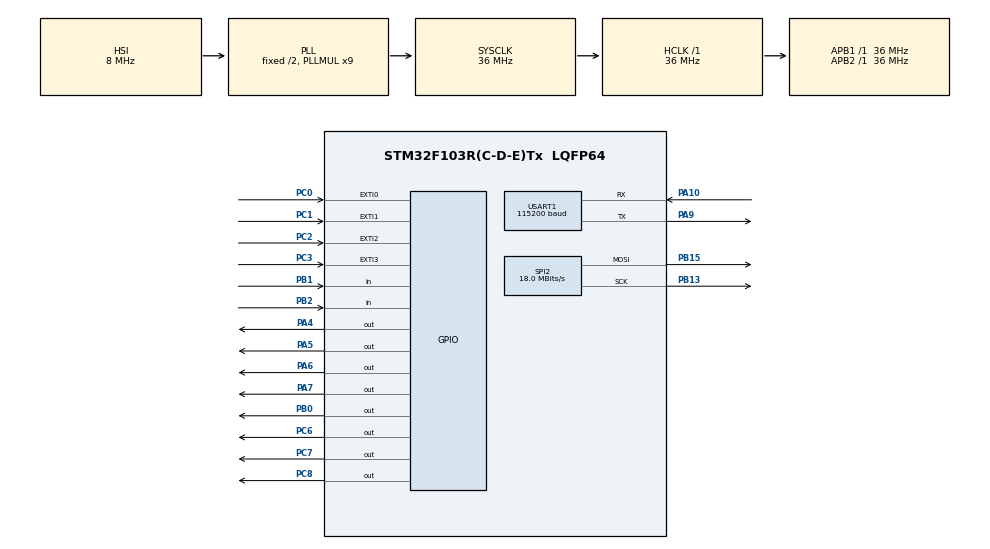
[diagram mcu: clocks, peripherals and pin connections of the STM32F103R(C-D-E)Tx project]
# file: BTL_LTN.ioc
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Mcu.Family=STM32F1
Mcu.Name=STM32F103R(C-D-E)Tx
Mcu.Package=LQFP64
NVIC.EXTI0_IRQn=true\:7\:0\:true\:false\:true\:true\:true\:true
NVIC.EXTI1_IRQn=true\:7\:0\:true\:false\:true\:true\:true\:true
NVIC.EXTI2_IRQn=true\:7\:0\:true\:false\:true\:true\:true\:true
NVIC.EXTI3_IRQn=true\:7\:0\:true\:false\:true\:true\:true\:true
NVIC.PriorityGroup=NVIC_PRIORITYGROUP_4
NVIC.SPI2_IRQn=true\:1\:0\:true\:false\:true\:true\:true\:true
NVIC.TIM1_UP_IRQn=true\:7\:0\:true\:false\:true\:true\:true\:true
NVIC.TIM4_IRQn=true\:15\:0\:false\:false\:true\:false\:true\:true
NVIC.TimeBase=TIM4_IRQn
NVIC.TimeBaseIP=TIM4
NVIC.USART1_IRQn=true\:6\:0\:true\:false\:true\:true\:true\:true
PA10.Mode=Asynchronous
PA10.Signal=USART1_RX
PA13.Mode=Serial_Wire
PA13.Signal=SYS_JTMS-SWDIO
PA14.Mode=Serial_Wire
PA14.Signal=SYS_JTCK-SWCLK
PA4.GPIO_ModeDefaultOutputPP=GPIO_MODE_OUTPUT_PP
PA4.GPIO_PuPd=GPIO_PULLUP
PA4.PinState=GPIO_PIN_SET
PA4.Signal=GPIO_Output
PA5.GPIO_PuPd=GPIO_PULLUP
PA5.PinState=GPIO_PIN_SET
PA5.Signal=GPIO_Output
PA6.GPIO_PuPd=GPIO_PULLUP
PA6.PinState=GPIO_PIN_SET
PA6.Signal=GPIO_Output
PA7.GPIO_PuPd=GPIO_PULLUP
PA7.PinState=GPIO_PIN_SET
PA7.Signal=GPIO_Output
PA9.Mode=Asynchronous
PA9.Signal=USART1_TX
PB0.GPIO_ModeDefaultOutputPP=GPIO_MODE_OUTPUT_OD
PB0.GPIO_PuPd=GPIO_PULLUP
PB0.PinState=GPIO_PIN_SET
PB0.Signal=GPIO_Output
PB1.GPIO_PuPd=GPIO_PULLUP
PB1.Signal=GPIO_Input
PB13.Mode=TX_Only_Simplex_Unidirect_Master
PB13.Signal=SPI2_SCK
PB15.Mode=TX_Only_Simplex_Unidirect_Master
PB15.Signal=SPI2_MOSI
PB2.GPIO_PuPd=GPIO_PULLUP
PB2.Signal=GPIO_Input
PC0.GPIO_ModeDefaultEXTI=GPIO_MODE_IT_FALLING
PC0.GPIO_PuPd=GPIO_PULLUP
PC0.Signal=GPXTI0
PC1.GPIO_ModeDefaultEXTI=GPIO_MODE_IT_FALLING
PC1.GPIO_PuPd=GPIO_PULLUP
PC1.Signal=GPXTI1
PC2.GPIO_ModeDefaultEXTI=GPIO_MODE_IT_FALLING
PC2.GPIO_PuPd=GPIO_PULLUP
PC2.Signal=GPXTI2
PC3.GPIO_ModeDefaultEXTI=GPIO_MODE_IT_FALLING
PC3.GPIO_PuPd=GPIO_PULLUP
PC3.Signal=GPXTI3
PC6.GPIO_PuPd=GPIO_PULLUP
PC6.Signal=GPIO_Output
PC7.GPIO_PuPd=GPIO_PULLUP
PC7.Signal=GPIO_Output
PC8.GPIO_PuPd=GPIO_PULLUP
PC8.Signal=GPIO_Output
PD0-OSC_IN.Mode=HSE-External-Oscillator
PD0-OSC_IN.Signal=RCC_OSC_IN
PD1-OSC_OUT.Mode=HSE-External-Oscillator
PD1-OSC_OUT.Signal=RCC_OSC_OUT
ProjectManager.HeapSize=0x200
ProjectManager.StackSize=0x400
ProjectManager.TargetToolchain=STM32CubeIDE
RCC.AHBFreq_Value=36000000
RCC.APB1Freq_Value=36000000
RCC.APB1TimFreq_Value=36000000
RCC.APB2Freq_Value=36000000
RCC.APB2TimFreq_Value=36000000
RCC.HCLKFreq_Value=36000000
RCC.PLLMUL=RCC_PLL_MUL9
RCC.SYSCLKFreq_VALUE=36000000
RCC.SYSCLKSource=RCC_SYSCLKSOURCE_PLLCLK
RCC.USBFreq_Value=36000000
SPI2.CalculateBaudRate=18.0 MBits/s
SPI2.Direction=SPI_DIRECTION_2LINES
SPI2.Mode=SPI_MODE_MASTER
SPI2.VirtualType=VM_MASTER
TIM1.AutoReloadPreload=TIM_AUTORELOAD_PRELOAD_ENABLE
TIM1.Period=10000
TIM1.Prescaler=35999
TIM2.Prescaler=35999
TIM3.Prescaler=35
USART1.BaudRate=115200
USART1.Parity=PARITY_NONE
USART1.VirtualMode=VM_ASYNC
VP_SYS_VS_tim4.Mode=TIM4
VP_TIM1_VS_ClockSourceINT.Mode=Internal
VP_TIM2_VS_ClockSourceINT.Mode=Internal
VP_TIM3_VS_ClockSourceINT.Mode=Internal
board=custom

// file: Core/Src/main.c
/* USER CODE BEGIN Header */
/**
  ******************************************************************************
  * @file           : main.c
  * @brief          : Main program body
  ******************************************************************************
  * @attention
  *
  * Copyright (c) 2024 STMicroelectronics.
  * All rights reserved.
  *
  * This software is licensed under terms that can be found in the LICENSE file
  * in the root directory of this software component.
  * If no LICENSE file comes with this software, it is provided AS-IS.
  *
  ******************************************************************************
  */
/* USER CODE END Header */
#include "main.h"

/* USER CODE BEGIN Includes */
#include "app.h"
/* USER CODE END Includes */

SPI_HandleTypeDef hspi2;

TIM_HandleTypeDef htim1;
TIM_HandleTypeDef htim2;
TIM_HandleTypeDef htim3;

UART_HandleTypeDef huart1;

void SystemClock_Config(void);
static void MX_GPIO_Init(void);
static void MX_TIM1_Init(void);
static void MX_TIM2_Init(void);
static void MX_TIM3_Init(void);
static void MX_SPI2_Init(void);
static void MX_USART1_UART_Init(void);

int main(void)
{

  /* MCU Configuration--------------------------------------------------------*/

  /* Reset of all peripherals, Initializes the Flash interface and the Systick. */
  HAL_Init();

  /* Configure the system clock */
  SystemClock_Config();

  /* Initialize all configured peripherals */
  MX_GPIO_Init();
  MX_TIM1_Init();
  MX_TIM2_Init();
  MX_TIM3_Init();
  MX_SPI2_Init();
  MX_USART1_UART_Init();
  /* USER CODE BEGIN 2 */
  App_Main();
  /* USER CODE END 2 */

  /* Infinite loop */
  while (1)
  {

  }
}

void SystemClock_Config(void)
{
  RCC_OscInitTypeDef RCC_OscInitStruct = {0};
  RCC_ClkInitTypeDef RCC_ClkInitStruct = {0};

  /** Initializes the RCC Oscillators according to the specified parameters
  * in the RCC_OscInitTypeDef structure.
  */
  RCC_OscInitStruct.OscillatorType = RCC_OSCILLATORTYPE_HSI;
  RCC_OscInitStruct.HSIState = RCC_HSI_ON;
  RCC_OscInitStruct.HSICalibrationValue = RCC_HSICALIBRATION_DEFAULT;
  RCC_OscInitStruct.PLL.PLLState = RCC_PLL_ON;
  RCC_OscInitStruct.PLL.PLLSource = RCC_PLLSOURCE_HSI_DIV2;
  RCC_OscInitStruct.PLL.PLLMUL = RCC_PLL_MUL9;
  if (HAL_RCC_OscConfig(&RCC_OscInitStruct) != HAL_OK)
  {
    Error_Handler();
  }

  /** Initializes the CPU, AHB and APB buses clocks
  */
  RCC_ClkInitStruct.ClockType = RCC_CLOCKTYPE_HCLK|RCC_CLOCKTYPE_SYSCLK
                              |RCC_CLOCKTYPE_PCLK1|RCC_CLOCKTYPE_PCLK2;
  RCC_ClkInitStruct.SYSCLKSource = RCC_SYSCLKSOURCE_PLLCLK;
  RCC_ClkInitStruct.AHBCLKDivider = RCC_SYSCLK_DIV1;
  RCC_ClkInitStruct.APB1CLKDivider = RCC_HCLK_DIV1;
  RCC_ClkInitStruct.APB2CLKDivider = RCC_HCLK_DIV1;

  if (HAL_RCC_ClockConfig(&RCC_ClkInitStruct, FLASH_LATENCY_1) != HAL_OK)
  {
    Error_Handler();
  }
}

static void MX_SPI2_Init(void)
{

  /* SPI2 parameter configuration*/
  hspi2.Instance = SPI2;
  hspi2.Init.Mode = SPI_MODE_MASTER;
  hspi2.Init.Direction = SPI_DIRECTION_2LINES;
  hspi2.Init.DataSize = SPI_DATASIZE_8BIT;
  hspi2.Init.CLKPolarity = SPI_POLARITY_LOW;
  hspi2.Init.CLKPhase = SPI_PHASE_1EDGE;
  hspi2.Init.NSS = SPI_NSS_SOFT;
  hspi2.Init.BaudRatePrescaler = SPI_BAUDRATEPRESCALER_2;
  hspi2.Init.FirstBit = SPI_FIRSTBIT_MSB;
  hspi2.Init.TIMode = SPI_TIMODE_DISABLE;
  hspi2.Init.CRCCalculation = SPI_CRCCALCULATION_DISABLE;
  hspi2.Init.CRCPolynomial = 10;
  if (HAL_SPI_Init(&hspi2) != HAL_OK)
  {
    Error_Handler();
  }

}

static void MX_TIM1_Init(void)
{

  TIM_ClockConfigTypeDef sClockSourceConfig = {0};
  TIM_MasterConfigTypeDef sMasterConfig = {0};

  htim1.Instance = TIM1;
  htim1.Init.Prescaler = 35999;
  htim1.Init.CounterMode = TIM_COUNTERMODE_UP;
  htim1.Init.Period = 10000;
  htim1.Init.ClockDivision = TIM_CLOCKDIVISION_DIV1;
  htim1.Init.RepetitionCounter = 0;
  htim1.Init.AutoReloadPreload = TIM_AUTORELOAD_PRELOAD_ENABLE;
  if (HAL_TIM_Base_Init(&htim1) != HAL_OK)
  {
    Error_Handler();
  }
  sClockSourceConfig.ClockSource = TIM_CLOCKSOURCE_INTERNAL;
  if (HAL_TIM_ConfigClockSource(&htim1, &sClockSourceConfig) != HAL_OK)
  {
    Error_Handler();
  }
  sMasterConfig.MasterOutputTrigger = TIM_TRGO_RESET;
  sMasterConfig.MasterSlaveMode = TIM_MASTERSLAVEMODE_DISABLE;
  if (HAL_TIMEx_MasterConfigSynchronization(&htim1, &sMasterConfig) != HAL_OK)
  {
    Error_Handler();
  }

}

static void MX_TIM2_Init(void)
{

  TIM_ClockConfigTypeDef sClockSourceConfig = {0};
  TIM_MasterConfigTypeDef sMasterConfig = {0};

  htim2.Instance = TIM2;
  htim2.Init.Prescaler = 35999;
  htim2.Init.CounterMode = TIM_COUNTERMODE_UP;
  htim2.Init.Period = 65535;
  htim2.Init.ClockDivision = TIM_CLOCKDIVISION_DIV1;
  htim2.Init.AutoReloadPreload = TIM_AUTORELOAD_PRELOAD_DISABLE;
  if (HAL_TIM_Base_Init(&htim2) != HAL_OK)
  {
    Error_Handler();
  }
  sClockSourceConfig.ClockSource = TIM_CLOCKSOURCE_INTERNAL;
  if (HAL_TIM_ConfigClockSource(&htim2, &sClockSourceConfig) != HAL_OK)
  {
    Error_Handler();
  }
  sMasterConfig.MasterOutputTrigger = TIM_TRGO_RESET;
  sMasterConfig.MasterSlaveMode = TIM_MASTERSLAVEMODE_DISABLE;
  if (HAL_TIMEx_MasterConfigSynchronization(&htim2, &sMasterConfig) != HAL_OK)
  {
    Error_Handler();
  }

}

static void MX_TIM3_Init(void)
{

  TIM_ClockConfigTypeDef sClockSourceConfig = {0};
  TIM_MasterConfigTypeDef sMasterConfig = {0};

  htim3.Instance = TIM3;
  htim3.Init.Prescaler = 35;
  htim3.Init.CounterMode = TIM_COUNTERMODE_UP;
  htim3.Init.Period = 65535;
  htim3.Init.ClockDivision = TIM_CLOCKDIVISION_DIV1;
  htim3.Init.AutoReloadPreload = TIM_AUTORELOAD_PRELOAD_DISABLE;
  if (HAL_TIM_Base_Init(&htim3) != HAL_OK)
  {
    Error_Handler();
  }
  sClockSourceConfig.ClockSource = TIM_CLOCKSOURCE_INTERNAL;
  if (HAL_TIM_ConfigClockSource(&htim3, &sClockSourceConfig) != HAL_OK)
  {
    Error_Handler();
  }
  sMasterConfig.MasterOutputTrigger = TIM_TRGO_RESET;
  sMasterConfig.MasterSlaveMode = TIM_MASTERSLAVEMODE_DISABLE;
  if (HAL_TIMEx_MasterConfigSynchronization(&htim3, &sMasterConfig) != HAL_OK)
  {
    Error_Handler();
  }

}

static void MX_USART1_UART_Init(void)
{

  huart1.Instance = USART1;
  huart1.Init.BaudRate = 115200;
  huart1.Init.WordLength = UART_WORDLENGTH_8B;
  huart1.Init.StopBits = UART_STOPBITS_1;
  huart1.Init.Parity = UART_PARITY_NONE;
  huart1.Init.Mode = UART_MODE_TX_RX;
  huart1.Init.HwFlowCtl = UART_HWCONTROL_NONE;
  huart1.Init.OverSampling = UART_OVERSAMPLING_16;
  if (HAL_UART_Init(&huart1) != HAL_OK)
  {
    Error_Handler();
  }

}

static void MX_GPIO_Init(void)
{
  GPIO_InitTypeDef GPIO_InitStruct = {0};

  /* GPIO Ports Clock Enable */
  __HAL_RCC_GPIOD_CLK_ENABLE();
  __HAL_RCC_GPIOC_CLK_ENABLE();
  __HAL_RCC_GPIOA_CLK_ENABLE();
  __HAL_RCC_GPIOB_CLK_ENABLE();

  /*Configure GPIO pin Output Level */
  HAL_GPIO_WritePin(GPIOA, GPIO_PIN_4|GPIO_PIN_5|GPIO_PIN_6|GPIO_PIN_7, GPIO_PIN_SET);

  /*Configure GPIO pin Output Level */
  HAL_GPIO_WritePin(GPIOB, GPIO_PIN_0, GPIO_PIN_SET);

  /*Configure GPIO pin Output Level */
  HAL_GPIO_WritePin(GPIOC, GPIO_PIN_6|GPIO_PIN_7|GPIO_PIN_8, GPIO_PIN_RESET);

  /*Configure GPIO pins : PC0 PC1 PC2 PC3 */
  GPIO_InitStruct.Pin = GPIO_PIN_0|GPIO_PIN_1|GPIO_PIN_2|GPIO_PIN_3;
  GPIO_InitStruct.Mode = GPIO_MODE_IT_FALLING;
  GPIO_InitStruct.Pull = GPIO_PULLUP;
  HAL_GPIO_Init(GPIOC, &GPIO_InitStruct);

  /*Configure GPIO pins : PA4 PA5 PA6 PA7 */
  GPIO_InitStruct.Pin = GPIO_PIN_4|GPIO_PIN_5|GPIO_PIN_6|GPIO_PIN_7;
  GPIO_InitStruct.Mode = GPIO_MODE_OUTPUT_PP;
  GPIO_InitStruct.Pull = GPIO_PULLUP;
  GPIO_InitStruct.Speed = GPIO_SPEED_FREQ_LOW;
  HAL_GPIO_Init(GPIOA, &GPIO_InitStruct);

  /*Configure GPIO pin : PB0 */
  GPIO_InitStruct.Pin = GPIO_PIN_0;
  GPIO_InitStruct.Mode = GPIO_MODE_OUTPUT_OD;
  GPIO_InitStruct.Pull = GPIO_PULLUP;
  GPIO_InitStruct.Speed = GPIO_SPEED_FREQ_LOW;
  HAL_GPIO_Init(GPIOB, &GPIO_InitStruct);

  /*Configure GPIO pins : PB1 PB2 */
  GPIO_InitStruct.Pin = GPIO_PIN_1|GPIO_PIN_2;
  GPIO_InitStruct.Mode = GPIO_MODE_INPUT;
  GPIO_InitStruct.Pull = GPIO_PULLUP;
  HAL_GPIO_Init(GPIOB, &GPIO_InitStruct);

  /*Configure GPIO pins : PC6 PC7 PC8 */
  GPIO_InitStruct.Pin = GPIO_PIN_6|GPIO_PIN_7|GPIO_PIN_8;
  GPIO_InitStruct.Mode = GPIO_MODE_OUTPUT_PP;
  GPIO_InitStruct.Pull = GPIO_PULLUP;
  GPIO_InitStruct.Speed = GPIO_SPEED_FREQ_LOW;
  HAL_GPIO_Init(GPIOC, &GPIO_InitStruct);

  /* EXTI interrupt init*/
  HAL_NVIC_SetPriority(EXTI0_IRQn, 7, 0);
  HAL_NVIC_EnableIRQ(EXTI0_IRQn);

  HAL_NVIC_SetPriority(EXTI1_IRQn, 7, 0);
  HAL_NVIC_EnableIRQ(EXTI1_IRQn);

  HAL_NVIC_SetPriority(EXTI2_IRQn, 7, 0);
  HAL_NVIC_EnableIRQ(EXTI2_IRQn);

  HAL_NVIC_SetPriority(EXTI3_IRQn, 7, 0);
  HAL_NVIC_EnableIRQ(EXTI3_IRQn);

}

void HAL_TIM_PeriodElapsedCallback(TIM_HandleTypeDef *htim)
{
  /* USER CODE BEGIN Callback 0 */
  relay_light_data_t relay_light_data_timer_give;
  BaseType_t higher_task_awoken = pdFALSE;
  /* USER CODE END Callback 0 */
  if (htim->Instance == TIM4) {
    HAL_IncTick();
  }
  /* USER CODE BEGIN Callback 1 */
  if (htim->Instance == TIM1)
  {
    HAL_TIM_Base_Stop_IT(&htim1);
    relay_light_data_timer_give = TIMER_GO_OFF;
    xQueueSendFromISR(queue_relay_light_data, &relay_light_data_timer_give, NULL);
    vTaskNotifyGiveFromISR(Task_Relay_Light_Handle, &higher_task_awoken);
    portYIELD_FROM_ISR(higher_task_awoken);
  }
  /* USER CODE END Callback 1 */
}

void Error_Handler(void)
{
  __disable_irq();
  while (1)
  {
  }
}
